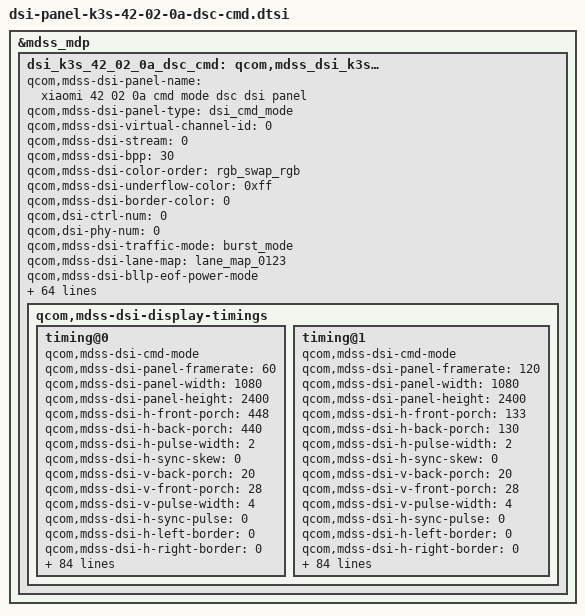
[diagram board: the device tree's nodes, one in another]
&mdss_mdp {
	dsi_k3s_42_02_0a_dsc_cmd: qcom,mdss_dsi_k3s_42_02_0a_dsc_cmd {
		qcom,mdss-dsi-panel-name = "xiaomi 42 02 0a cmd mode dsc dsi panel";
		qcom,mdss-dsi-panel-type = "dsi_cmd_mode";
		qcom,mdss-dsi-virtual-channel-id = <0>;
		qcom,mdss-dsi-stream = <0>;
		qcom,mdss-dsi-bpp = <30>;
		qcom,mdss-dsi-color-order = "rgb_swap_rgb";
		qcom,mdss-dsi-underflow-color = <0xff>;
		qcom,mdss-dsi-border-color = <0>;

		qcom,dsi-ctrl-num = <0>;
		qcom,dsi-phy-num = <0>;

		qcom,mdss-dsi-traffic-mode = "burst_mode";
		qcom,mdss-dsi-lane-map = "lane_map_0123";
		qcom,mdss-dsi-bllp-eof-power-mode;
		qcom,mdss-dsi-bllp-power-mode;
		qcom,mdss-dsi-lane-0-state;
		qcom,mdss-dsi-lane-1-state;
		qcom,mdss-dsi-lane-2-state;
		qcom,mdss-dsi-lane-3-state;
		qcom,mdss-dsi-dma-trigger = "trigger_sw";
		qcom,mdss-dsi-mdp-trigger = "none";
		qcom,mdss-dsi-reset-sequence = <0 10>, <1 10>, <0 1>, <1 10>;
		qcom,mdss-pan-physical-width-dimension = <695>;
		qcom,mdss-pan-physical-height-dimension = <1545>;
		qcom,mdss-dsi-te-pin-select = <1>;
		qcom,mdss-dsi-wr-mem-start = <0x2c>;
		qcom,mdss-dsi-wr-mem-continue = <0x3c>;
		qcom,mdss-dsi-te-dcs-command = <1>;
		qcom,mdss-dsi-te-check-enable;
		qcom,mdss-dsi-te-using-te-pin;
		qcom,mdss-dsi-tx-eot-append;
		qcom,mdss-dsi-lp11-init;

		qcom,mdss-dsi-panel-mode-switch;

		qcom,mdss-dsi-bl-inverted-dbv;
		qcom,bl-update-flag = "delay_until_first_frame";

		qcom,mdss-dsi-panel-hdr-enabled;
		qcom,mdss-dsi-panel-hdr-color-primaries = <14500 15500 32000
			17000 15500 30000 8000 3000>;
		qcom,mdss-dsi-panel-peak-brightness = <4200000>;
		qcom,mdss-dsi-panel-blackness-level = <3230>;

		qcom,mdss-dsi-display-timings {
			timing@0{
				qcom,mdss-dsi-cmd-mode;
				qcom,mdss-dsi-panel-framerate = <60>;
				qcom,mdss-dsi-panel-width = <1080>;
				qcom,mdss-dsi-panel-height = <2400>;
				qcom,mdss-dsi-h-front-porch = <448>;
				qcom,mdss-dsi-h-back-porch = <440>;
				qcom,mdss-dsi-h-pulse-width = <2>;
				qcom,mdss-dsi-h-sync-skew = <0>;
				qcom,mdss-dsi-v-back-porch = <20>;
				qcom,mdss-dsi-v-front-porch = <28>;
				qcom,mdss-dsi-v-pulse-width = <4>;
				qcom,mdss-dsi-h-sync-pulse = <0>;
				qcom,mdss-dsi-h-left-border = <0>;
				qcom,mdss-dsi-h-right-border = <0>;
				qcom,mdss-dsi-v-top-border = <0>;
				qcom,mdss-dsi-v-bottom-border = <0>;
				qcom,mdss-dsi-panel-clockrate = <1100000000>;
				qcom,mdss-dsi-panel-jitter = <0x5 0x1>;
				qcom,mdss-mdp-transfer-time-us = <14000>;
				qcom,mdss-dsi-on-command = [
					/* ESD */
					39 01 00 00 00 00 06 F0 55 AA 52 08 00
					39 01 00 00 00 00 02 6F 05
					39 01 00 00 00 00 02 BE 08
					/* 5. DSC Setting */
					39 01 00 00 00 00 02 90 01
					39 01 00 00 00 00 13 91 AB A8 00 0C C2 00 03 1C 01 7E 00 0F 08 BB 04 3D 10 F0
					39 01 00 00 00 00 02 03 01
					39 01 00 00 00 00 02 2C 00
					/* Round ON */
					39 01 00 00 00 00 06 F0 55 AA 52 08 07
					39 01 00 00 00 00 03 C0 01 02
					/* 3. Common Setting */
					/* 3.1 TE ON Setting */
					39 01 00 00 00 00 02 35 00                           /* TE On(Vsync) */
					/* 3.2 CASET/RASET Setting */
					39 01 00 00 00 00 05 2A 00 00 04 37                  /* CASET 1080 */
					39 01 00 00 00 00 05 2B 00 00 09 5F                  /* PASET 2400 */
					/* 3.3 Dimming  ON Setting */
					39 01 00 00 00 00 02 53 28
					/* 3.3.1 Adjusting dimming speed */
					39 00 00 00 00 00 06 F0 55 AA 52 08 00
					39 00 00 00 00 00 02 6F 02
					39 01 00 00 00 00 03 B2 08 08
					/* 3.4 Frame Rate 60Hz */
					39 01 00 00 00 00 02 2F 01
					/* 3.6 MIPI Speed = 1100Mbps @osc 127.9525Mhz */
					39 01 00 00 00 00 06 F0 55 AA 52 08 01
					39 01 00 00 00 00 08 C3 9B 01 94 D0 22 02 00
					/* PMIC Fast Discharge On */
					39 01 00 00 00 00 06 F0 55 AA 52 08 00
					39 01 00 00 00 00 02 6F 06
					39 01 00 00 00 00 04 B5 2B 0C 32
					/* 4. User Command Set */
					/* Sleep Out */
					39 01 00 00 78 00 02 11 00
					/* Display On */
					39 01 00 00 00 00 02 29 00];
				qcom,mdss-dsi-on-command-state = "dsi_lp_mode";
				qcom,mdss-dsi-off-command = [
					39 01 00 00 00 00 02 28 00
					39 01 00 00 64 00 02 10 00];
				qcom,mdss-dsi-off-command-state = "dsi_lp_mode";

				qcom,mdss-dsi-timing-switch-command = [
					/* Frame Rate 60Hz */
					39 01 00 00 09 00 02 2F 01
				];
				qcom,mdss-dsi-timing-switch-command-state = "dsi_lp_mode";

				qcom,mdss-dsi-nolp-command = [
					39 01 00 00 00 00 05 51 00 00 00 00
					39 00 00 00 00 00 06 F0 55 AA 52 08 00
					39 00 00 00 00 00 02 B2 18
					/* AOD off */
					39 00 00 00 00 00 02 65 00
					39 00 00 00 00 00 02 38 00
					39 00 00 00 00 00 02 2C 00
					39 00 00 00 00 00 02 2F 01
					39 00 00 00 00 00 06 F0 55 AA 52 08 01
					39 01 00 00 00 00 02 CE 0C
				];
				qcom,mdss-dsi-nolp-command-state = "dsi_lp_mode";

				qcom,compression-mode = "dsc";
				qcom,mdss-dsc-version = <0x12>;
				qcom,mdss-dsc-scr-version = <0x0>;
				qcom,mdss-dsc-slice-height = <12>;
				qcom,mdss-dsc-slice-width = <1080>;
				qcom,mdss-dsc-slice-per-pkt = <2>;
				qcom,mdss-dsc-bit-per-component = <10>;
				qcom,mdss-dsc-bit-per-pixel = <8>;
				qcom,mdss-dsc-block-prediction-enable;
			};
			timing@1{
				qcom,mdss-dsi-cmd-mode;
				qcom,mdss-dsi-panel-framerate = <120>;
				qcom,mdss-dsi-panel-width = <1080>;
				qcom,mdss-dsi-panel-height = <2400>;
				qcom,mdss-dsi-h-front-porch = <133>;
				qcom,mdss-dsi-h-back-porch = <130>;
				qcom,mdss-dsi-h-pulse-width = <2>;
				qcom,mdss-dsi-h-sync-skew = <0>;
				qcom,mdss-dsi-v-back-porch = <20>;
				qcom,mdss-dsi-v-front-porch = <28>;
				qcom,mdss-dsi-v-pulse-width = <4>;
				qcom,mdss-dsi-h-sync-pulse = <0>;
				qcom,mdss-dsi-h-left-border = <0>;
				qcom,mdss-dsi-h-right-border = <0>;
				qcom,mdss-dsi-v-top-border = <0>;
				qcom,mdss-dsi-v-bottom-border = <0>;
				qcom,mdss-dsi-panel-clockrate = <1100000000>;
				qcom,mdss-dsi-panel-jitter = <0x5 0x1>;
				qcom,mdss-mdp-transfer-time-us = <7000>;
				qcom,mdss-dsi-on-command = [
					/* ESD */
					39 01 00 00 00 00 06 F0 55 AA 52 08 00
					39 01 00 00 00 00 02 6F 05
					39 01 00 00 00 00 02 BE 08
					/* 5. DSC Setting */
					39 01 00 00 00 00 02 90 01
					39 01 00 00 00 00 13 91 AB A8 00 0C C2 00 03 1C 01 7E 00 0F 08 BB 04 3D 10 F0
					39 01 00 00 00 00 02 03 01
					39 01 00 00 00 00 02 2C 00
					/* Round ON */
					39 01 00 00 00 00 06 F0 55 AA 52 08 07
					39 01 00 00 00 00 03 C0 01 02
					/* 3. Common Setting */
					/* 3.1 TE ON Setting */
					39 01 00 00 00 00 02 35 00                           /* TE On(Vsync) */
					/* 3.2 CASET/RASET Setting */
					39 01 00 00 00 00 05 2A 00 00 04 37                  /* CASET 1080 */
					39 01 00 00 00 00 05 2B 00 00 09 5F                  /* PASET 2400 */
					/* 3.3 Dimming  ON Setting */
					39 01 00 00 00 00 02 53 28
					/* 3.3.1 Adjusting dimming speed */
					39 00 00 00 00 00 06 F0 55 AA 52 08 00
					39 00 00 00 00 00 02 6F 02
					39 01 00 00 00 00 03 B2 08 08
					/* 3.4 Frame Rate 120Hz */
					39 01 00 00 00 00 02 2F 02
					/* 3.6 MIPI Speed = 1100Mbps @osc 127.9525Mhz */
					39 01 00 00 00 00 06 F0 55 AA 52 08 01
					39 01 00 00 00 00 08 C3 9B 01 94 D0 22 02 00
					/* Fast Discharge On */
					39 01 00 00 00 00 06 F0 55 AA 52 08 00
					39 01 00 00 00 00 02 6F 06
					39 01 00 00 00 00 04 B5 2B 0C 32
					/* 4. User Command Set */
					/* Sleep Out */
					39 01 00 00 78 00 02 11 00                           /* Sleep Out */
					/* Display On */
					39 01 00 00 00 00 02 29 00];
				qcom,mdss-dsi-on-command-state = "dsi_lp_mode";
				qcom,mdss-dsi-off-command = [
					39 01 00 00 00 00 02 28 00
					39 01 00 00 64 00 02 10 00];
				qcom,mdss-dsi-off-command-state = "dsi_lp_mode";

				qcom,mdss-dsi-timing-switch-command = [
					/* Frame Rate 120Hz */
					39 01 00 00 11 00 02 2F 02
				];
				qcom,mdss-dsi-timing-switch-command-state = "dsi_lp_mode";

				qcom,mdss-dsi-nolp-command = [
					39 01 00 00 00 00 05 51 00 00 00 00
					39 00 00 00 00 00 06 F0 55 AA 52 08 00
					39 00 00 00 00 00 02 B2 18
					/* AOD off */
					39 00 00 00 00 00 02 65 00
					39 00 00 00 00 00 02 38 00
					39 00 00 00 00 00 02 2C 00
					39 00 00 00 00 00 02 2F 02
					39 00 00 00 00 00 06 F0 55 AA 52 08 01
					39 01 00 00 00 00 02 CE 0C
				];
				qcom,mdss-dsi-nolp-command-state = "dsi_lp_mode";

				qcom,compression-mode = "dsc";
				qcom,mdss-dsc-version = <0x12>;
				qcom,mdss-dsc-scr-version = <0x0>;
				qcom,mdss-dsc-slice-height = <12>;
				qcom,mdss-dsc-slice-width = <1080>;
				qcom,mdss-dsc-slice-per-pkt = <2>;
				qcom,mdss-dsc-bit-per-component = <10>;
				qcom,mdss-dsc-bit-per-pixel = <8>;
				qcom,mdss-dsc-block-prediction-enable;
			};
		};
	};
};

&dsi_k3s_42_02_0a_dsc_cmd {
	mi,panel-id = <0x004B3353 0x00420200>;
	mi,hbm-51-ctl-flag;
	mi,hbm-off-51-index = <0>;
	mi,hbm-on-51-index = <0>;
	mi,hbm-bl-min-level = <1>;
	mi,hbm-bl-max-level = <2047>;
	mi,max-brightness-clone = <8191>;
	mi,fp-display-on-optimize-flag;
	mi,aod-hbm-51-index = <8>;
	mi,aod-lbm-51-index = <8>;
	mi,panel-aod-to-off-command-need-enabled;

	mi,mdss-dsi-panel-dc-type = <0>;
	mi,dc-update-flag;
	mi,dc-on-60hz-d2-index = <10>;
	mi,dc-on-120hz-d4-index = <11>;
	mi,dc-off-60hz-d2-index = <6>;
	mi,dc-off-120hz-d4-index = <7>;

	mi,flatmode-update-flag;
	mi,flatmode-on-b9-index = <3>;

	/* IRQF_ONESHOT | IRQF_TRIGGER_RISING */
	mi,esd-err-irq-gpio = <&tlmm 75 0x2001>;
	qcom,esd-check-enabled;
	qcom,esd-aod-check-enabled;
	qcom,mdss-dsi-panel-status-check-mode = "reg_read";
	qcom,mdss-dsi-panel-status-offset-command = [
		39 01 00 00 00 00 05 FF AA 55 A5 81
		39 01 00 00 00 00 02 6F 0F];
	qcom,mdss-dsi-panel-status-command = [
		06 01 00 01 00 00 01 FA
		06 01 00 01 00 00 01 91];
	qcom,mdss-dsi-panel-status-read-length = <1 18>;
	qcom,mdss-dsi-panel-max-error-count = <3>;
	qcom,mdss-dsi-panel-status-value =
		<0x00>,
		<0xAB 0xA8 0x00 0x0C 0xC2 0x00 0x03 0x1C 0x01 0x7E 0x00 0x0F 0x08 0xBB 0x04 0x3D 0x10 0xF0>;
	qcom,mdss-dsi-panel-status-command-state = "dsi_lp_mode";
	qcom,mdss-dsi-panel-status-offset-command-state = "dsi_lp_mode";

	mi,panel-on-dimming-delay = <120>;

	//mi,mdss-dsi-panel-dc-threshold = <450>;
	// mi,mdss-dsi-panel-hbm-brightness = <1>;

	qcom,mdss-dsi-display-timings {
		timing@0 {
			mi,mdss-dsc-panel-id = <0x004B3353 0x00420200>;
			mi,mdss-dsi-dimmingon-command = [39 01 00 00 00 00 02 53 28];
			mi,mdss-dsi-dimmingon-command-state = "dsi_hs_mode";
			mi,mdss-dsi-dimmingoff-command = [39 01 00 00 00 00 02 53 20];
			mi,mdss-dsi-dimmingoff-command-state = "dsi_hs_mode";
			mi,mdss-dsi-hbm-on-command = [39 01 00 00 00 00 03 51 0F FF];
			mi,mdss-dsi-hbm-on-command-state = "dsi_lp_mode";
			mi,mdss-dsi-hbm-off-command = [39 01 00 00 00 00 03 51 07 FF];
			mi,mdss-dsi-hbm-off-command-state = "dsi_lp_mode";

			mi,mdss-dsi-doze-hbm-command = [
				/* Frame Rate 60Hz */
				39 01 00 00 00 00 02 2F 01
				/* GIR OFF */
				39 00 00 00 00 00 06 F0 55 AA 52 08 08
				39 00 00 00 00 00 02 6F 07
				39 00 00 00 00 00 05 B9 00 00 00 3D
				/*AOD on*/
				39 00 00 00 00 00 06 F0 55 AA 52 08 00
				39 00 00 00 00 00 02 B2 08
				39 01 00 00 32 00 02 39 00
				39 00 00 00 00 00 02 65 01
				39 01 00 00 00 00 05 51 01 06 0F FF
			];
			mi,mdss-dsi-doze-hbm-command-state = "dsi_lp_mode";
			mi,mdss-dsi-doze-lbm-command = [
				/* Frame Rate 60Hz */
				39 01 00 00 00 00 02 2F 01
				/* GIR OFF */
				39 00 00 00 00 00 06 F0 55 AA 52 08 08
				39 00 00 00 00 00 02 6F 07
				39 00 00 00 00 00 05 B9 00 00 00 3D
				/*AOD on*/
				39 00 00 00 00 00 06 F0 55 AA 52 08 00
				39 00 00 00 00 00 02 B2 08
				39 01 00 00 32 00 02 39 00
				39 00 00 00 00 00 02 65 01
				39 01 00 00 00 00 05 51 00 24 01 55
			];
			mi,mdss-dsi-doze-lbm-command-state = "dsi_lp_mode";

			mi,mdss-dsi-pre-doze-to-off-command = [
				39 01 00 00 00 00 06 F0 55 AA 52 08 01
				39 01 00 00 00 00 02 CE 0C];
			mi,mdss-dsi-pre-doze-to-off-command-state = "dsi_lp_mode";

			mi,mdss-dsi-switch-page4-command = [
				/* Set page 4 */
				39 01 00 00 00 00 06 F0 55 AA 52 08 04];
			mi,mdss-dsi-switch-page4-command-state = "dsi_lp_mode";
			mi,mdss-dsi-dc-on-command = [
				/* Set page 0 */
				39 01 00 00 00 00 06 F0 55 AA 52 08 00
				39 00 00 00 00 00 02 B2 98
				39 00 00 00 00 00 02 6F 0F
				/* 1 pulse */
				39 00 00 00 00 00 09 B2 00 00 01 47 01 47 00 00
				39 00 00 00 00 00 25 B3
					00 00 00 00 00 00 00 00 00 00 00 00 00 00 00 00
					00 00 00 00 00 00 00 00 00 00 00 00 00 00 00 00
					07 FF 0F FF
				39 00 00 00 00 00 02 6F AC
				39 00 00 00 00 00 47 B2
					00 00 01 0A 01 6C 01 B6 01 F3 02 28 02 58 02 84
					02 AC 02 D2 02 F5 03 17 03 37 04 E0 06 09 06 FA
					07 C9 08 81 09 28 09 C1 0A 51 0A D7 0B 56 0B CF
					0C 42 0C B0 0D 1A 0D 80 0D E3 0E 42 0E 9F 0E F9
					0F 50 0F A5 0F FF
				39 00 00 00 00 00 02 6F 52
				39 00 00 00 00 00 45 B3
					00 05 00 0A 00 0F 00 14 00 19 00 1E 00 23 00 28
					00 2D 00 32 00 37 00 3C 00 96 00 F0 01 4A 01 A4
					01 FE 02 58 02 B2 03 0C 03 66 03 C0 04 1A 04 74
					04 CE 05 28 05 82 05 DC 06 36 06 90 06 EA 07 44
					07 9E 07 FF
				/* Set page 4 */
				39 00 00 00 00 00 06 F0 55 AA 52 08 04
				/* Enter_DC_LUT @ 60Hz */
				/* need read 0xD2 to update */
				39 00 00 00 00 00 4C D2
					00 00 00 00 00 00 00 00 00 00 00 00 00 00 00 00
					00 00 00 00 00 00 00 00 00 00 00 00 00 00 00 00
					00 00 00 00 00 00 00 00 00 00 00 00 00 00 00 00
					00 00 00 00 00 00 00 00 00 00 00 00 00 00 00 00
					00 00 00 00 00 00 00 00 00 00 00
				/* Enter_DC_LUT @ 120Hz */
				/* need read 0xD4 to update */
				39 01 00 00 00 00 4C D4
					00 00 00 00 00 00 00 00 00 00 00 00 00 00 00 00
					00 00 00 00 00 00 00 00 00 00 00 00 00 00 00 00
					00 00 00 00 00 00 00 00 00 00 00 00 00 00 00 00
					00 00 00 00 00 00 00 00 00 00 00 00 00 00 00 00
					00 00 00 00 00 00 00 00 00 00 00
			];
			mi,mdss-dsi-dc-on-command-state = "dsi_lp_mode";
			mi,mdss-dsi-dc-off-command = [
				/* Set page 0 */
				39 01 00 00 00 00 06 F0 55 AA 52 08 00
				39 00 00 00 00 00 02 B2 18
				39 00 00 00 00 00 02 6F 0F
				/* 4 pulse */
				39 00 00 00 00 00 09 B2 20 20 21 47 21 47 20 00
				39 00 00 00 00 00 25 B3
					00 08 00 18 00 18 00 31 00 31 00 62 00 62 00 C0
					00 C0 01 32 01 32 01 47 01 47 03 33 03 33 07 FF
					07 FF 0F FF
				/* Set page 4 */
				39 00 00 00 00 00 06 F0 55 AA 52 08 04
				/* Exit_DC_LUT @ 60Hz */
				/* Use the read 0xD2 parameters(Driver IC OTP) */
				39 00 00 00 00 00 4C D2
					00 00 00 00 00 00 00 00 00 00 00 00 00 00 00 00
					00 00 00 00 00 00 00 00 00 00 00 00 00 00 00 00
					00 00 00 00 00 00 00 00 00 00 00 00 00 00 00 00
					00 00 00 00 00 00 00 00 00 00 00 00 00 00 00 00
					00 00 00 00 00 00 00 00 00 00 00
				/* Exit_DC_LUT @ 120Hz */
				/* Use the read 0xD4 parameters(Driver IC OTP) */
				39 01 00 00 00 00 4C D4
					00 00 00 00 00 00 00 00 00 00 00 00 00 00 00 00
					00 00 00 00 00 00 00 00 00 00 00 00 00 00 00 00
					00 00 00 00 00 00 00 00 00 00 00 00 00 00 00 00
					00 00 00 00 00 00 00 00 00 00 00 00 00 00 00 00
					00 00 00 00 00 00 00 00 00 00 00
			];
			mi,mdss-dsi-dc-off-command-state = "dsi_lp_mode";

			mi,mdss-dsi-flat-mode-read-pre-command = [
				/* set page 0 */
				39 01 00 00 00 00 06 F0 55 AA 52 08 00
				/* set register offset */
				39 01 00 00 00 00 02 6F 3F];
			mi,mdss-dsi-flat-mode-read-pre-command-state = "dsi_lp_mode";
			mi,mdss-dsi-flat-mode-on-command = [
				/* GIR ON , 60Hz */
				39 00 00 00 00 00 02 2F 03
				/* set page 8 */
				39 00 00 00 00 00 06 F0 55 AA 52 08 08
				39 00 00 00 00 00 02 6F 07
				/* must to use read flatmode parameter to update */
				39 00 00 00 00 00 05 B9 00 00 00 00
				/* Demura Gain switch */
				39 00 00 00 00 00 06 F0 55 AA 52 08 00
				39 00 00 00 00 00 02 6F 08
				39 01 00 00 00 00 02 C0 44];
			mi,mdss-dsi-flat-mode-on-command-state = "dsi_hs_mode";
			mi,mdss-dsi-flat-mode-off-command = [
				/* GIR OFF , 60Hz */
				39 00 00 00 00 00 02 2F 01
				39 00 00 00 00 00 06 F0 55 AA 52 08 08
				39 00 00 00 00 00 02 6F 07
				39 00 00 00 00 00 05 B9 00 00 00 3D
				/* Demura Gain switch */
				39 00 00 00 00 00 06 F0 55 AA 52 08 00
				39 00 00 00 00 00 02 6F 08
				39 01 00 00 00 00 02 C0 40];
			mi,mdss-dsi-flat-mode-off-command-state = "dsi_hs_mode";
			mi,mdss-dsi-timing-switch-gir-command = [
				/* Frame Rate 60Hz GIR ON */
				39 01 00 00 09 00 02 2F 03
			];
			mi,mdss-dsi-timing-switch-gir-command-state = "dsi_hs_mode";

			mi,mdss-dsi-aod-to-dc-on-command = [
				39 01 00 00 00 00 06 F0 55 AA 52 08 00
				39 01 00 00 00 00 02 B2 98];
			mi,mdss-dsi-aod-to-dc-on-command-state = "dsi_hs_mode";
		};
		timing@1 {
			mi,mdss-dsc-panel-id = <0x004B3353 0x00420200>;
			mi,mdss-dsi-dimmingon-command = [39 01 00 00 00 00 02 53 28];
			mi,mdss-dsi-dimmingon-command-state = "dsi_hs_mode";
			mi,mdss-dsi-dimmingoff-command = [39 01 00 00 00 00 02 53 20];
			mi,mdss-dsi-dimmingoff-command-state = "dsi_hs_mode";

			mi,mdss-dsi-hbm-on-command = [39 01 00 00 00 00 03 51 0F FF];
			mi,mdss-dsi-hbm-on-command-state = "dsi_lp_mode";
			mi,mdss-dsi-hbm-off-command = [39 01 00 00 00 00 03 51 07 FF];
			mi,mdss-dsi-hbm-off-command-state = "dsi_lp_mode";

			mi,mdss-dsi-doze-hbm-command = [
				/* Frame Rate 60Hz */
				39 01 00 00 00 00 02 2F 01
				/* GIR OFF */
				39 00 00 00 00 00 06 F0 55 AA 52 08 08
				39 00 00 00 00 00 02 6F 07
				39 00 00 00 00 00 05 B9 00 00 00 3D
				/*AOD on*/
				39 00 00 00 00 00 06 F0 55 AA 52 08 00
				39 00 00 00 00 00 02 B2 08
				39 01 00 00 32 00 02 39 00
				39 00 00 00 00 00 02 65 01
				39 01 00 00 00 00 05 51 01 06 0F FF
			];
			mi,mdss-dsi-doze-hbm-command-state = "dsi_lp_mode";
			mi,mdss-dsi-doze-lbm-command = [
				/* Frame Rate 60Hz */
				39 01 00 00 00 00 02 2F 01
				/* GIR OFF */
				39 00 00 00 00 00 06 F0 55 AA 52 08 08
				39 00 00 00 00 00 02 6F 07
				39 00 00 00 00 00 05 B9 00 00 00 3D
				/*AOD on*/
				39 00 00 00 00 00 06 F0 55 AA 52 08 00
				39 00 00 00 00 00 02 B2 08
				39 01 00 00 32 00 02 39 00
				39 00 00 00 00 00 02 65 01
				39 01 00 00 00 00 05 51 00 24 01 55
			];
			mi,mdss-dsi-doze-lbm-command-state = "dsi_lp_mode";

			mi,mdss-dsi-pre-doze-to-off-command = [
				39 01 00 00 00 00 06 F0 55 AA 52 08 01
				39 01 00 00 00 00 02 CE 0C];
			mi,mdss-dsi-pre-doze-to-off-command-state = "dsi_lp_mode";

			mi,mdss-dsi-switch-page4-command = [
				/* Set page 4 */
				39 01 00 00 00 00 06 F0 55 AA 52 08 04];
			mi,mdss-dsi-switch-page4-command-state = "dsi_lp_mode";
			mi,mdss-dsi-dc-on-command = [
				/* Set page 0 */
				39 01 00 00 00 00 06 F0 55 AA 52 08 00
				39 00 00 00 00 00 02 B2 98
				39 00 00 00 00 00 02 6F 0F
				/* 1 pulse */
				39 00 00 00 00 00 09 B2 00 00 01 47 01 47 00 00
				39 00 00 00 00 00 25 B3
					00 00 00 00 00 00 00 00 00 00 00 00 00 00 00 00
					00 00 00 00 00 00 00 00 00 00 00 00 00 00 00 00
					07 FF 0F FF
				39 00 00 00 00 00 02 6F AC
				39 00 00 00 00 00 47 B2
					00 00 01 0A 01 6C 01 B6 01 F3 02 28 02 58 02 84
					02 AC 02 D2 02 F5 03 17 03 37 04 E0 06 09 06 FA
					07 C9 08 81 09 28 09 C1 0A 51 0A D7 0B 56 0B CF
					0C 42 0C B0 0D 1A 0D 80 0D E3 0E 42 0E 9F 0E F9
					0F 50 0F A5 0F FF
				39 00 00 00 00 00 02 6F 52
				39 00 00 00 00 00 45 B3
					00 05 00 0A 00 0F 00 14 00 19 00 1E 00 23 00 28
					00 2D 00 32 00 37 00 3C 00 96 00 F0 01 4A 01 A4
					01 FE 02 58 02 B2 03 0C 03 66 03 C0 04 1A 04 74
					04 CE 05 28 05 82 05 DC 06 36 06 90 06 EA 07 44
					07 9E 07 FF
				/* Set page 4 */
				39 00 00 00 00 00 06 F0 55 AA 52 08 04
				/* Enter_DC_LUT @ 60Hz */
				/* need read 0xD2 to update */
				39 00 00 00 00 00 4C D2
					00 00 00 00 00 00 00 00 00 00 00 00 00 00 00 00
					00 00 00 00 00 00 00 00 00 00 00 00 00 00 00 00
					00 00 00 00 00 00 00 00 00 00 00 00 00 00 00 00
					00 00 00 00 00 00 00 00 00 00 00 00 00 00 00 00
					00 00 00 00 00 00 00 00 00 00 00
				/* Enter_DC_LUT @ 120Hz */
				/* need read 0xD4 to update */
				39 01 00 00 00 00 4C D4
					00 00 00 00 00 00 00 00 00 00 00 00 00 00 00 00
					00 00 00 00 00 00 00 00 00 00 00 00 00 00 00 00
					00 00 00 00 00 00 00 00 00 00 00 00 00 00 00 00
					00 00 00 00 00 00 00 00 00 00 00 00 00 00 00 00
					00 00 00 00 00 00 00 00 00 00 00
			];
			mi,mdss-dsi-dc-on-command-state = "dsi_lp_mode";
			mi,mdss-dsi-dc-off-command = [
				/* Set page 0 */
				39 01 00 00 00 00 06 F0 55 AA 52 08 00
				39 00 00 00 00 00 02 B2 18
				39 00 00 00 00 00 02 6F 0F
				/* 4 pulse */
				39 00 00 00 00 00 09 B2 30 20 31 47 21 47 20 00
				39 00 00 00 00 00 25 B3
					00 08 00 18 00 18 00 31 00 31 00 62 00 62 00 C0
					00 C0 01 32 01 32 01 47 01 47 03 33 03 33 07 FF
					07 FF 0F FF
				/* Set page 4 */
				39 00 00 00 00 00 06 F0 55 AA 52 08 04
				/* Exit_DC_LUT @ 120Hz */
				/* Use the read 0xD2 parameters(Driver IC OTP) */
				39 00 00 00 00 00 4C D2
					00 00 00 00 00 00 00 00 00 00 00 00 00 00 00 00
					00 00 00 00 00 00 00 00 00 00 00 00 00 00 00 00
					00 00 00 00 00 00 00 00 00 00 00 00 00 00 00 00
					00 00 00 00 00 00 00 00 00 00 00 00 00 00 00 00
					00 00 00 00 00 00 00 00 00 00 00
				/* Use the read 0xD4 parameters(Driver IC OTP) */
				39 01 00 00 00 00 4C D4
					00 00 00 00 00 00 00 00 00 00 00 00 00 00 00 00
					00 00 00 00 00 00 00 00 00 00 00 00 00 00 00 00
					00 00 00 00 00 00 00 00 00 00 00 00 00 00 00 00
					00 00 00 00 00 00 00 00 00 00 00 00 00 00 00 00
					00 00 00 00 00 00 00 00 00 00 00
			];
			mi,mdss-dsi-dc-off-command-state = "dsi_lp_mode";

			mi,mdss-dsi-flat-mode-read-pre-command = [
				/* set page 0 */
				39 01 00 00 00 00 06 F0 55 AA 52 08 00
				/* set register offset */
				39 01 00 00 00 00 02 6F 3F];
			mi,mdss-dsi-flat-mode-read-pre-command-state = "dsi_lp_mode";
			mi,mdss-dsi-flat-mode-on-command = [
				/* GIR ON , 120Hz */
				39 00 00 00 00 00 02 2F 04
				/* set page 8 */
				39 00 00 00 00 00 06 F0 55 AA 52 08 08
				39 00 00 00 00 00 02 6F 07
				/* must to use read flatmode parameter to update */
				39 00 00 00 00 00 05 B9 00 00 00 00
				/* Demura Gain switch */
				39 00 00 00 00 00 06 F0 55 AA 52 08 00
				39 00 00 00 00 00 02 6F 08
				39 01 00 00 00 00 02 C0 44];
			mi,mdss-dsi-flat-mode-on-command-state = "dsi_hs_mode";
			mi,mdss-dsi-flat-mode-off-command = [
				/* GIR OFF , 120Hz */
				39 00 00 00 00 00 02 2F 02
				39 00 00 00 00 00 06 F0 55 AA 52 08 08
				39 00 00 00 00 00 02 6F 07
				39 00 00 00 00 00 05 B9 00 00 00 3D
				/* Demura Gain switch */
				39 00 00 00 00 00 06 F0 55 AA 52 08 00
				39 00 00 00 00 00 02 6F 08
				39 01 00 00 00 00 02 C0 40];
			mi,mdss-dsi-flat-mode-off-command-state = "dsi_hs_mode";
			mi,mdss-dsi-timing-switch-gir-command = [
				/* Frame Rate 120Hz GIR ON */
				39 01 00 00 11 00 02 2F 04];
			mi,mdss-dsi-timing-switch-gir-command-state = "dsi_hs_mode";

			mi,mdss-dsi-aod-to-dc-on-command = [
				39 01 00 00 00 00 06 F0 55 AA 52 08 00
				39 01 00 00 00 00 02 B2 98];
			mi,mdss-dsi-aod-to-dc-on-command-state = "dsi_hs_mode";
		};
	};
};
